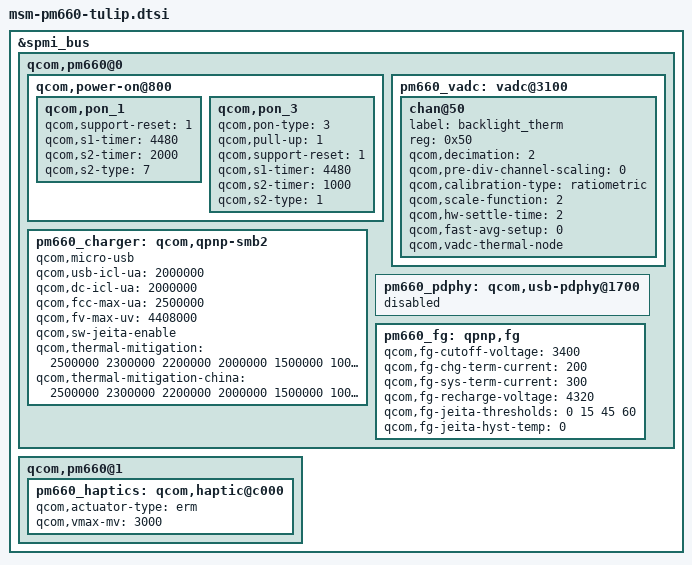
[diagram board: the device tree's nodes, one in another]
/* Copyright (c) 2016-2017, The Linux Foundation. All rights reserved.
 * Copyright (C) 2018 XiaoMi, Inc.
 *
 * This program is free software; you can redistribute it and/or modify
 * it under the terms of the GNU General Public License version 2 and
 * only version 2 as published by the Free Software Foundation.
 *
 * This program is distributed in the hope that it will be useful,
 * but WITHOUT ANY WARRANTY; without even the implied warranty of
 * MERCHANTABILITY or FITNESS FOR A PARTICULAR PURPOSE.  See the
 * GNU General Public License for more details.
 */

&spmi_bus {
	qcom,pm660@0 {
		qcom,power-on@800 {
			qcom,pon_1 {
				qcom,support-reset = <1>;
				qcom,s1-timer = <4480>;
				qcom,s2-timer = <2000>;
				qcom,s2-type = <7>;
			};
			qcom,pon_3 {
				qcom,pon-type = <3>;
				qcom,pull-up = <1>;
				qcom,support-reset = <1>;
				qcom,s1-timer = <4480>;
				qcom,s2-timer = <1000>;
				qcom,s2-type = <1>;
			};
		};
		pm660_vadc: vadc@3100 {
                       chan@50 {
				label = "backlight_therm";
				reg = <0x50>;
				qcom,decimation = <2>;
				qcom,pre-div-channel-scaling = <0>;
				qcom,calibration-type = "ratiometric";
				qcom,scale-function = <2>;
				qcom,hw-settle-time = <2>;
				qcom,fast-avg-setup = <0>;
				qcom,vadc-thermal-node;
			};
		};
		pm660_charger: qcom,qpnp-smb2 {
			qcom,micro-usb;

			qcom,usb-icl-ua = <2000000>;
			qcom,dc-icl-ua = <2000000>;
			qcom,fcc-max-ua = <2500000>;
			qcom,fv-max-uv  = <4408000>;
			qcom,sw-jeita-enable;

			qcom,thermal-mitigation
					= <2500000 2300000 2200000 2000000 1500000 1000000 800000 400000 100000>;
			qcom,thermal-mitigation-china
					= <2500000 2300000 2200000 2000000 1500000 1000000 800000 400000 100000>;

		};
		pm660_pdphy: qcom,usb-pdphy@1700 {
			status = "disabled";
		};
		pm660_fg: qpnp,fg {
			qcom,fg-cutoff-voltage = <3400>;
			qcom,fg-chg-term-current = <200>;
			qcom,fg-sys-term-current = <300>;
			qcom,fg-recharge-voltage = <4320>;

			qcom,fg-jeita-thresholds = <0 15 45 60>;
			qcom,fg-jeita-hyst-temp = <0>;
		};
	};
	qcom,pm660@1 {
		pm660_haptics: qcom,haptic@c000 {
			qcom,actuator-type = "erm";
			qcom,vmax-mv = <3000>;
		};
	};
};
